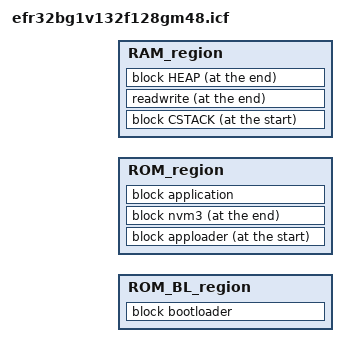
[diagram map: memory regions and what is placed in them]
/*###ICF### Section handled by ICF editor, don't touch! ****/
/*-Editor annotation file-*/
/* IcfEditorFile="$TOOLKIT_DIR$\config\ide\IcfEditor\cortex_v1_0.xml" */

/*-Memory Regions-*/
define symbol __ICFEDIT_region_ROM_BL_start__   = 0x0000;
define symbol __ICFEDIT_region_ROM_BL_end__     = (0x0000+0x4000-1);
define symbol __ICFEDIT_region_ROM_start__   = 0x4000;
define symbol __ICFEDIT_region_ROM_end__     = (0x00020000-1);
define symbol __ICFEDIT_region_RAM_start__   = 0x20000000;
define symbol __ICFEDIT_region_RAM_end__     = (0x20000000+0x00004000-1);

/*-Sizes-*/
if (!isdefinedsymbol(__STACK_SIZE))
{
  define symbol __STACK_SIZE      = 0x800;
}
if (!isdefinedsymbol(__HEAP_SIZE))
{
  define symbol __HEAP_SIZE        = 0xD00;
}
/**** End of ICF editor section. ###ICF###*/

define memory mem with size = 4G;
define region ROM_BL_region   = mem:[from __ICFEDIT_region_ROM_BL_start__ to __ICFEDIT_region_ROM_BL_end__];
define region ROM_region   = mem:[from __ICFEDIT_region_ROM_start__ to __ICFEDIT_region_ROM_end__];
define region RAM_region   = mem:[from __ICFEDIT_region_RAM_start__ to __ICFEDIT_region_RAM_end__];

define block CSTACK    with alignment = 8, size = __STACK_SIZE   { };
define block HEAP      with alignment = 8, size = __HEAP_SIZE     { };

initialize by copy { readwrite };
do not initialize  { section .noinit };


define block apploader with alignment = 2048
{
  readonly section .binapploader
};
define block bootloader with size=0x4000
{
  readonly section .binbootloader,
};

define block nvm3
{
  section SIMEE,
};

define block application with fixed order, alignment = 2048
{
  readonly section .intvec,  
  readonly section .application_properties,
  readonly 
};

keep { section .intvec };
keep { section .application_properties };
keep { section .binbootloader };
keep { section .binapploader };

".text_bootloader":
place in ROM_BL_region  { block bootloader };

".text_apploader":
place at start of ROM_region  { block apploader };

".text_nvm3":
place at end of ROM_region  { block nvm3 };

".text_application":
place in ROM_region   { block application };

place at start of RAM_region  { block CSTACK };

place at end of RAM_region   { readwrite,
                               block HEAP };
                        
